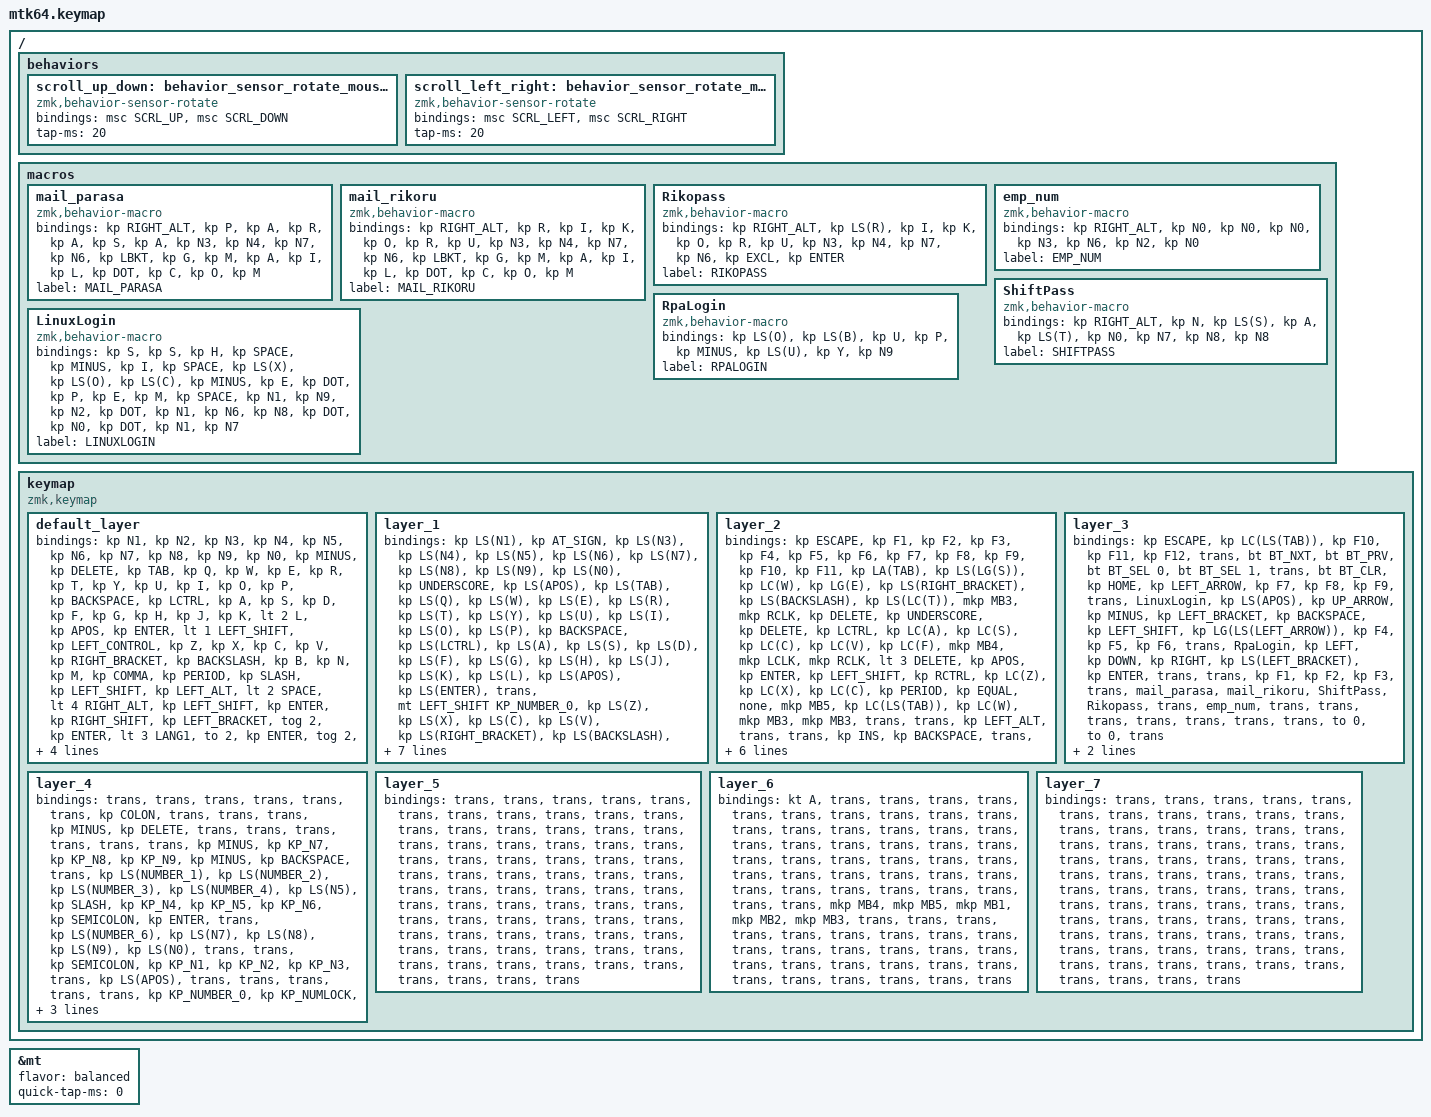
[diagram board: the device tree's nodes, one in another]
#include "keycode_japanese.h"
#include <behaviors.dtsi>
#include <dt-bindings/zmk/bt.h>
#include <dt-bindings/zmk/keys.h>
#include <dt-bindings/zmk/pointing.h>

// スクロール量の設定

#define ZMK_POINTING_DEFAULT_SCRL_VAL 100

&mt {
    flavor = "balanced";
    quick-tap-ms = <0>;
};

/ {
    behaviors {
        // 垂直スクロール用のbehaviorの設定

        scroll_up_down: behavior_sensor_rotate_mouse_wheel_up_down {
            compatible = "zmk,behavior-sensor-rotate";
            #sensor-binding-cells = <0>;
            bindings = <&msc SCRL_UP>, <&msc SCRL_DOWN>;

            tap-ms = <20>; // スクロールのタップ時間
        };

        // 水平スクロール用のbehaviorの設定

        scroll_left_right: behavior_sensor_rotate_mouse_wheel_left_right {
            compatible = "zmk,behavior-sensor-rotate";
            #sensor-binding-cells = <0>;
            bindings = <&msc SCRL_LEFT>, <&msc SCRL_RIGHT>;

            tap-ms = <20>; // スクロールのタップ時間
        };
    };
};

/ {
    macros {
        mail_parasa: mail_parasa {
            compatible = "zmk,behavior-macro";
            #binding-cells = <0>;
            bindings = <&kp RIGHT_ALT &kp P &kp A &kp R &kp A &kp S &kp A &kp N3 &kp N4 &kp N7 &kp N6 &kp LBKT &kp G &kp M &kp A &kp I &kp L &kp DOT &kp C &kp O &kp M>;
            label = "MAIL_PARASA";
        };

        mail_rikoru: mail_rikoru {
            compatible = "zmk,behavior-macro";
            #binding-cells = <0>;
            bindings = <&kp RIGHT_ALT &kp R &kp I &kp K &kp O &kp R &kp U &kp N3 &kp N4 &kp N7 &kp N6 &kp LBKT &kp G &kp M &kp A &kp I &kp L &kp DOT &kp C &kp O &kp M>;
            label = "MAIL_RIKORU";
        };

        Rikopass: Rikopass {
            compatible = "zmk,behavior-macro";
            #binding-cells = <0>;
            bindings = <&kp RIGHT_ALT &kp LS(R) &kp I &kp K &kp O &kp R &kp U &kp N3 &kp N4 &kp N7 &kp N6 &kp EXCL &kp ENTER>;
            label = "RIKOPASS";
        };

        emp_num: emp_num {
            compatible = "zmk,behavior-macro";
            #binding-cells = <0>;
            bindings = <&kp RIGHT_ALT &kp N0 &kp N0 &kp N0 &kp N3 &kp N6 &kp N2 &kp N0>;
            label = "EMP_NUM";
        };

        ShiftPass: ShiftPass {
            compatible = "zmk,behavior-macro";
            #binding-cells = <0>;
            bindings = <&kp RIGHT_ALT &kp N &kp LS(S) &kp A &kp LS(T) &kp N0 &kp N7 &kp N8 &kp N8>;
            label = "SHIFTPASS";
        };

        RpaLogin: RpaLogin {
            compatible = "zmk,behavior-macro";
            #binding-cells = <0>;
            bindings = <&kp LS(O) &kp LS(B) &kp U &kp P &kp MINUS &kp LS(U) &kp Y &kp N9>;
            label = "RPALOGIN";
        };

        LinuxLogin: LinuxLogin {
            compatible = "zmk,behavior-macro";
            #binding-cells = <0>;
            bindings = <&kp S &kp S &kp H &kp SPACE &kp MINUS &kp I &kp SPACE &kp LS(X) &kp LS(O) &kp LS(C) &kp MINUS &kp E &kp DOT &kp P &kp E &kp M &kp SPACE &kp N1 &kp N9 &kp N2 &kp DOT &kp N1 &kp N6 &kp N8 &kp DOT &kp N0 &kp DOT &kp N1 &kp N7>;
            label = "LINUXLOGIN";
        };
    };

    keymap {
        compatible = "zmk,keymap";

        default_layer {
            bindings = <
&kp N1  &kp N2  &kp N3  &kp N4  &kp N5  &kp N6  &kp N7  &kp N8  &kp N9  &kp N0  &kp MINUS  &kp DELETE  &kp TAB  &kp Q  &kp W  &kp E  &kp R  &kp T  &kp Y  &kp U  &kp I  &kp O  &kp P  &kp BACKSPACE  &kp LCTRL  &kp A  &kp S  &kp D  &kp F  &kp G  &kp H  &kp J  &kp K  &lt 2 L  &kp APOS  &kp ENTER  &lt 1 LEFT_SHIFT  &kp LEFT_CONTROL  &kp Z  &kp X  &kp C  &kp V  &kp RIGHT_BRACKET  &kp BACKSLASH  &kp B  &kp N  &kp M  &kp COMMA  &kp PERIOD  &kp SLASH  &kp LEFT_SHIFT  &kp LEFT_ALT  &lt 2 SPACE  &lt 4 RIGHT_ALT  &kp LEFT_SHIFT  &kp ENTER  &kp RIGHT_SHIFT  &kp LEFT_BRACKET  &tog 2  &kp ENTER  &lt 3 LANG1  &to 2  &kp ENTER  &tog 2  &lt 1 RIGHT_ALT  &to 3  &mo 1  &mo 2  &mo 3  &mo 1  &mo 2  &mo 3  &mo 1  &mo 2  &mo 3
            >;

            sensor-bindings =
                <&inc_dec_kp PAGE_UP PAGE_DOWN>,
                <&inc_dec_kp UP_ARROW DOWN_ARROW>;
        };

        layer_1 {
            bindings = <
&kp LS(N1)  &kp AT_SIGN  &kp LS(N3)  &kp LS(N4)  &kp LS(N5)  &kp LS(N6)  &kp LS(N7)  &kp LS(N8)  &kp LS(N9)  &kp LS(N0)  &kp UNDERSCORE  &kp LS(APOS)  &kp LS(TAB)  &kp LS(Q)  &kp LS(W)  &kp LS(E)  &kp LS(R)  &kp LS(T)  &kp LS(Y)  &kp LS(U)  &kp LS(I)  &kp LS(O)  &kp LS(P)  &kp BACKSPACE  &kp LS(LCTRL)  &kp LS(A)  &kp LS(S)  &kp LS(D)  &kp LS(F)  &kp LS(G)  &kp LS(H)  &kp LS(J)  &kp LS(K)  &kp LS(L)  &kp LS(APOS)  &kp LS(ENTER)  &trans  &mt LEFT_SHIFT KP_NUMBER_0  &kp LS(Z)  &kp LS(X)  &kp LS(C)  &kp LS(V)  &kp LS(RIGHT_BRACKET)  &kp LS(BACKSLASH)  &kp LS(B)  &kp LS(N)  &kp LS(M)  &kp LS(COMMA)  &kp LS(PERIOD)  &kp LS(SLASH)  &kp LS(LCTRL)  &kp LS(LEFT_ALT)  &trans  &trans  &trans  &trans  &kp RIGHT_GUI  &kp LS(LEFT_BRACKET)  &trans  &trans  &trans  &trans  &trans  &trans  &trans  &trans  &trans  &trans  &trans  &trans  &trans  &trans  &trans  &trans  &trans
            >;
        };

        layer_2 {
            bindings = <
&kp ESCAPE  &kp F1  &kp F2  &kp F3  &kp F4  &kp F5  &kp F6  &kp F7  &kp F8  &kp F9  &kp F10  &kp F11  &kp LA(TAB)  &kp LS(LG(S))  &kp LC(W)  &kp LG(E)  &kp LS(RIGHT_BRACKET)  &kp LS(BACKSLASH)  &kp LS(LC(T))  &mkp MB3  &mkp RCLK  &kp DELETE  &kp UNDERSCORE  &kp DELETE  &kp LCTRL  &kp LC(A)  &kp LC(S)  &kp LC(C)  &kp LC(V)  &kp LC(F)  &mkp MB4  &mkp LCLK  &mkp RCLK  &lt 3 DELETE  &kp APOS  &kp ENTER  &kp LEFT_SHIFT  &kp RCTRL  &kp LC(Z)  &kp LC(X)  &kp LC(C)  &kp PERIOD  &kp EQUAL  &none  &mkp MB5  &kp LC(LS(TAB))  &kp LC(W)  &mkp MB3  &mkp MB3  &trans  &trans  &kp LEFT_ALT  &trans  &trans  &kp INS  &kp BACKSPACE  &trans  &trans  &trans  &trans  &trans  &to 0  &trans  &trans  &trans  &kp LC(LS(TAB))  &trans  &trans  &trans  &trans  &trans  &trans  &trans  &trans  &trans
            >;

            sensor-bindings = <
                &inc_dec_kp TAB LC(TAB) 
                &inc_dec_kp PG_UP PG_DN
            >;
        };

        layer_3 {
            bindings = <
&kp ESCAPE  &kp LC(LS(TAB))  &kp F10  &kp F11  &kp F12  &trans  &bt BT_NXT  &bt BT_PRV  &bt BT_SEL 0  &bt BT_SEL 1  &trans  &bt BT_CLR  &kp HOME  &kp LEFT_ARROW  &kp F7  &kp F8  &kp F9  &trans  &LinuxLogin  &kp LS(APOS)  &kp UP_ARROW  &kp MINUS  &kp LEFT_BRACKET  &kp BACKSPACE  &kp LEFT_SHIFT  &kp LG(LS(LEFT_ARROW))  &kp F4  &kp F5  &kp F6  &trans  &RpaLogin  &kp LEFT  &kp DOWN  &kp RIGHT  &kp LS(LEFT_BRACKET)  &kp ENTER  &trans  &trans  &kp F1  &kp F2  &kp F3  &trans  &mail_parasa  &mail_rikoru  &ShiftPass  &Rikopass  &trans  &emp_num  &trans  &trans  &trans  &trans  &trans  &trans  &trans  &to 0  &to 0  &trans
            >;

            sensor-bindings = <
                &scroll_left_right
                &scroll_up_down
            >;
        };

        layer_4 {
            bindings = <
&trans  &trans  &trans  &trans  &trans  &trans  &kp COLON  &trans  &trans  &trans  &kp MINUS  &kp DELETE  &trans  &trans  &trans  &trans  &trans  &trans  &kp MINUS  &kp KP_N7  &kp KP_N8  &kp KP_N9  &kp MINUS  &kp BACKSPACE  &trans  &kp LS(NUMBER_1)  &kp LS(NUMBER_2)  &kp LS(NUMBER_3)  &kp LS(NUMBER_4)  &kp LS(N5)  &kp SLASH  &kp KP_N4  &kp KP_N5  &kp KP_N6  &kp SEMICOLON  &kp ENTER  &trans  &kp LS(NUMBER_6)  &kp LS(N7)  &kp LS(N8)  &kp LS(N9)  &kp LS(N0)  &trans  &trans  &kp SEMICOLON  &kp KP_N1  &kp KP_N2  &kp KP_N3  &trans  &kp LS(APOS)  &trans  &trans  &trans  &trans  &trans  &kp KP_NUMBER_0  &kp KP_NUMLOCK  &trans  &trans  &trans  &trans  &trans  &trans  &trans  &trans  &trans  &trans  &trans  &trans  &trans  &trans  &trans  &trans  &trans  &trans
            >;
        };

        layer_5 {
            bindings = <
&trans  &trans  &trans  &trans  &trans  &trans  &trans  &trans  &trans  &trans  &trans  &trans  &trans  &trans  &trans  &trans  &trans  &trans  &trans  &trans  &trans  &trans  &trans  &trans  &trans  &trans  &trans  &trans  &trans  &trans  &trans  &trans  &trans  &trans  &trans  &trans  &trans  &trans  &trans  &trans  &trans  &trans  &trans  &trans  &trans  &trans  &trans  &trans  &trans  &trans  &trans  &trans  &trans  &trans  &trans  &trans  &trans  &trans  &trans  &trans  &trans  &trans  &trans  &trans  &trans  &trans  &trans  &trans  &trans  &trans  &trans  &trans  &trans  &trans  &trans
            >;
        };

        layer_6 {
            bindings = <
&kt A  &trans  &trans  &trans  &trans  &trans  &trans  &trans  &trans  &trans  &trans  &trans  &trans  &trans  &trans  &trans  &trans  &trans  &trans  &trans  &trans  &trans  &trans  &trans  &trans  &trans  &trans  &trans  &trans  &trans  &trans  &trans  &trans  &trans  &trans  &trans  &trans  &trans  &trans  &trans  &trans  &trans  &trans  &mkp MB4  &mkp MB5  &mkp MB1  &mkp MB2  &mkp MB3  &trans  &trans  &trans  &trans  &trans  &trans  &trans  &trans  &trans  &trans  &trans  &trans  &trans  &trans  &trans  &trans  &trans  &trans  &trans  &trans  &trans  &trans  &trans  &trans  &trans  &trans  &trans
            >;
        };

        layer_7 {
            bindings = <
&trans  &trans  &trans  &trans  &trans  &trans  &trans  &trans  &trans  &trans  &trans  &trans  &trans  &trans  &trans  &trans  &trans  &trans  &trans  &trans  &trans  &trans  &trans  &trans  &trans  &trans  &trans  &trans  &trans  &trans  &trans  &trans  &trans  &trans  &trans  &trans  &trans  &trans  &trans  &trans  &trans  &trans  &trans  &trans  &trans  &trans  &trans  &trans  &trans  &trans  &trans  &trans  &trans  &trans  &trans  &trans  &trans  &trans  &trans  &trans  &trans  &trans  &trans  &trans  &trans  &trans  &trans  &trans  &trans  &trans  &trans  &trans  &trans  &trans  &trans
            >;
        };
    };
};
